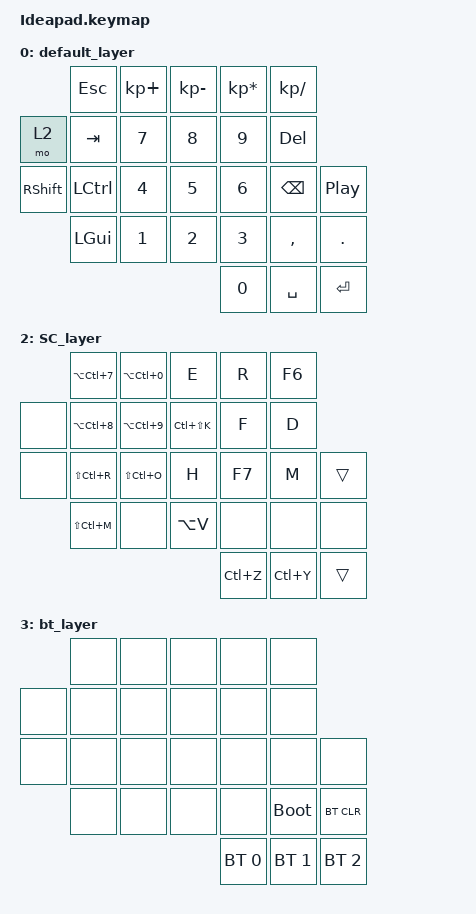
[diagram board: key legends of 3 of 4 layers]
#include <behaviors.dtsi>
#include <dt-bindings/zmk/bt.h>
#include <dt-bindings/zmk/keys.h>

#define default_layer 0
#define Nav_layer     1
#define SC_layer      2
#define bt_layer      3

#define NONE 0

/ {

    combos {
        compatible = "zmk,combos";

        Layer_1 {
            timeout-ms = <100>;
            bindings = <&to 1>;
            key-positions = <0 5>;
        };

        Layer_3 {
            timeout-ms = <100>;
            bindings = <&to 3>;
            key-positions = <1 5>;
        };

        Copy {
            timeout-ms = <100>;
            bindings = <&kp LC(C)>;
            key-positions = <11 14>;
        };

        Paste {
            timeout-ms = <100>;
            bindings = <&kp LC(V)>;
            key-positions = <11 15>;  
        };
    };


    keymap {
        compatible = "zmk,keymap";

        default_layer {

// --------------------------------------------------------------------------------------------------------------------------------------------------------------------
//           |   Esc   |    +    |    -    |    *    |    /    |
// | SC Lay  |   Tab   |    7    |    8    |    9    |    del  |
// | RShift  |  LCtrl  |    4    |    5    |    6    |    BS   |  PLay   |
//           | Windows |    1    |    2    |    3    |    ,    |    .    |
//                                         |    0    |  Space  |  Enter  |

            bindings = <
              &kp ESC             &kp KP_PLUS     &kp KP_MINUS    &kp KP_MULTIPLY &kp KP_DIVIDE
&mo 2         &kp TAB             &kp NUMBER_7    &kp NUMBER_8    &kp NUMBER_9    &kp DELETE
&kp RSHIFT    &kp LEFT_CONTROL    &kp NUMBER_4    &kp NUMBER_5    &kp NUMBER_6    &kp BACKSPACE    &kp C_PLAY_PAUSE
              &kp LGUI            &kp NUMBER_1    &kp NUMBER_2    &kp NUMBER_3    &kp COMMA        &kp DOT
                                                                  &kp NUMBER_0    &kp SPACE        &kp ENTER
            >;
            sensor-bindings = <&inc_dec_kp C_VOLUME_DOWN C_VOLUME_UP>;
        };

        Nav_layer {
            bindings = <
               &to 0          &kp C_BRIGHTNESS_DEC  &kp C_BRIGHTNESS_INC  &kp C_PREVIOUS  &kp C_NEXT
&kp RA (N8)    &kp RA (N9)    &kp TAB               &kp ESC               &none       &trans
&kp RA (N7)    &kp RA (N0)    &kp Q                 &kp W                 &kp E       &trans          &none
               &kp LSHFT      &kp A                 &kp S                 &kp D       &kp F3          &trans
                                                                          &none       &trans          &trans
            >;
            sensor-bindings = <&inc_dec_kp LEFT RIGHT>;
        };

        SC_layer {
            bindings = < 
             &kp LA(LC(NUMBER_7))  &kp LA(LC(NUMBER_0))  &kp E           &kp R           &kp F6
&none        &kp LA(LC(NUMBER_8))  &kp LA(LC(NUMBER_9))  &kp LC(LS(K))   &kp F           &kp D
&none        &kp LS(LC(R))         &kp LS(LC(O))         &kp H           &kp F7          &kp M       &trans
             &kp LS(LC(M))         &none                 &kp LA(V)       &none           &none       &none
                                                                         &kp LC(Z)       &kp LC(Y)   &trans
            >;
        }; 

        bt_layer {
            bindings = <
       &none  &none  &none  &none         &none
&none  &none  &none  &none  &none         &none
&none  &none  &none  &none  &none         &none         &none
       &none  &none  &none  &none         &bootloader   &bt BT_CLR
                            &bt BT_SEL 0  &bt BT_SEL 1  &bt BT_SEL 2
            >;
        };
    };
};
